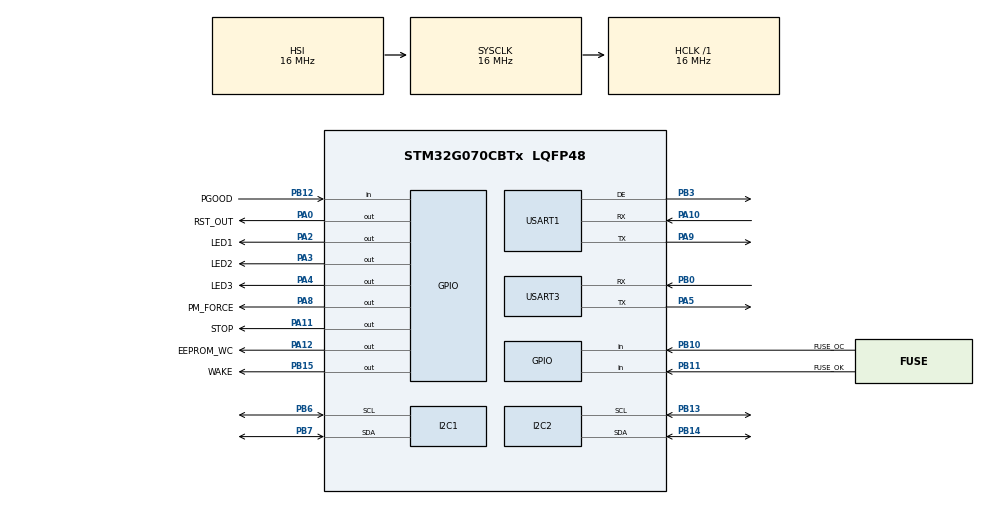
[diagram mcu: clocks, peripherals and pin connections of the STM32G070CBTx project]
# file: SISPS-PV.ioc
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Mcu.Family=STM32G0
Mcu.Name=STM32G070CBTx
Mcu.Package=LQFP48
PA0.GPIO_Label=RST_OUT
PA0.GPIO_ModeDefaultOutputPP=GPIO_MODE_OUTPUT_OD
PA0.GPIO_PuPd=GPIO_NOPULL
PA0.PinState=GPIO_PIN_SET
PA0.Signal=GPIO_Output
PA10.Mode=Asynchronous
PA10.Signal=USART1_RX
PA11\ [PA9].GPIO_Label=STOP
PA11\ [PA9].Signal=GPIO_Output
PA12\ [PA10].GPIO_Label=EEPROM_WC
PA12\ [PA10].PinState=GPIO_PIN_SET
PA12\ [PA10].Signal=GPIO_Output
PA13.Mode=Serial_Wire
PA13.Signal=SYS_SWDIO
PA14-BOOT0.Mode=Serial_Wire
PA14-BOOT0.Signal=SYS_SWCLK
PA2.GPIO_Label=LED1
PA2.Signal=GPIO_Output
PA3.GPIO_Label=LED2
PA3.Signal=GPIO_Output
PA4.GPIO_Label=LED3
PA4.Signal=GPIO_Output
PA5.Mode=Asynchronous
PA5.Signal=USART3_TX
PA8.GPIO_Label=PM_FORCE
PA8.Signal=GPIO_Output
PA9.Mode=Asynchronous
PA9.Signal=USART1_TX
PB0.Mode=Asynchronous
PB0.Signal=USART3_RX
PB10.GPIO_Label=FUSE_OC
PB10.Signal=GPIO_Input
PB11.GPIO_Label=FUSE_OK
PB11.Signal=GPIO_Input
PB12.GPIO_Label=PGOOD
PB12.Signal=GPIO_Input
PB13.Mode=I2C
PB13.Signal=I2C2_SCL
PB14.Mode=I2C
PB14.Signal=I2C2_SDA
PB15.GPIO_Label=WAKE
PB15.Signal=GPIO_Output
PB3.Mode=Hardware Flow Control (RS485)
PB3.Signal=USART1_DE
PB6.Mode=I2C
PB6.Signal=I2C1_SCL
PB7.Mode=I2C
PB7.Signal=I2C1_SDA
ProjectManager.HeapSize=0x200
ProjectManager.StackSize=0x400
ProjectManager.TargetToolchain=STM32CubeIDE
RCC.AHBFreq_Value=16000000
RCC.CortexFreq_Value=16000000
RCC.EXTERNAL_CLOCK_VALUE=48000
RCC.HCLKFreq_Value=16000000
RCC.HSE_VALUE=8000000
RCC.HSI_VALUE=16000000
RCC.LSE_VALUE=32768
RCC.SYSCLKFreq_VALUE=16000000
RCC.VCOOutputFreq_Value=128000000
USART1.VirtualMode-Asynchronous=VM_ASYNC
USART1.VirtualMode-Hardware\ Flow\ Control\ (RS485)=VM_ASYNC
USART3.SwapParam=ADVFEATURE_SWAP_ENABLE
USART3.VirtualMode-Asynchronous=VM_ASYNC
VP_SYS_VS_DBSignals.Mode=DisableDeadBatterySignals
board=custom

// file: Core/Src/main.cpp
/* USER CODE BEGIN Header */
/**
 ******************************************************************************
 * @file           : main.cpp
 * @brief          : Main program file for SISPS-PV.
 * @author			: Lawrence Stanton
 ******************************************************************************
 * @attention
 *
 * © LD Stanton 2022
 *
 * This file and its content are the copyright property of the author. All
 * rights are reserved. No warranty is given. No liability is assumed.
 * Confidential unless licensed otherwise. If licensed, refer to the
 * accompanying file "LICENCE" for license details.
 *
 * Copyright (c) 2022 STMicroelectronics.
 * All rights reserved.
 *
 ******************************************************************************
 */
/* USER CODE END Header */
#include "main.hpp"

/* USER CODE BEGIN Includes */
#include "SISPSPV.hpp"
/* USER CODE END Includes */

/* USER CODE BEGIN PTD */
using namespace std;

/* USER CODE END PTD */

I2C_HandleTypeDef hi2c1;
I2C_HandleTypeDef hi2c2;

UART_HandleTypeDef huart1;
UART_HandleTypeDef huart3;

/* USER CODE BEGIN PV */
I2C_HandleTypeDef *sm72445_hi2c = &hi2c2;
I2C_HandleTypeDef *tmp116_hi2c = &hi2c1;
I2C_HandleTypeDef *hdc1080_hi2c = &hi2c2;
/* USER CODE END PV */

void SystemClock_Config(void);
static void MX_GPIO_Init(void);
static void MX_I2C1_Init(void);
static void MX_I2C2_Init(void);
static void MX_USART1_UART_Init(void);
static void MX_USART3_UART_Init(void);

/* USER CODE BEGIN 0 */
TMP116 tmp = TMP116(TMP116::I2CAddr::ADDR0);
/* USER CODE END 0 */

int main(void) {

	/* MCU Configuration--------------------------------------------------------*/

	/* Reset of all peripherals, Initializes the Flash interface and the Systick. */
	HAL_Init();

	/* Configure the system clock */
	SystemClock_Config();

	/* Initialize all configured peripherals */
	MX_GPIO_Init();
	MX_I2C1_Init();
	MX_I2C2_Init();
	MX_USART1_UART_Init();
	MX_USART3_UART_Init();
	/* USER CODE BEGIN 2 */
	uint16_t devID;
	float T;
	UNUSED(devID);
	UNUSED(T);
	tmp.setConversionMode();

	/* USER CODE END 2 */

	/* Infinite loop */
	while (1) {
		devID = tmp.getDevID();
		T = tmp.getTemperature();
		HAL_Delay(100);
	}
}

void SystemClock_Config(void) {
	RCC_OscInitTypeDef RCC_OscInitStruct = { 0 };
	RCC_ClkInitTypeDef RCC_ClkInitStruct = { 0 };

	/** Configure the main internal regulator output voltage
	 */
	HAL_PWREx_ControlVoltageScaling(PWR_REGULATOR_VOLTAGE_SCALE1);

	/** Initializes the RCC Oscillators according to the specified parameters
	 * in the RCC_OscInitTypeDef structure.
	 */
	RCC_OscInitStruct.OscillatorType = RCC_OSCILLATORTYPE_HSI;
	RCC_OscInitStruct.HSIState = RCC_HSI_ON;
	RCC_OscInitStruct.HSIDiv = RCC_HSI_DIV1;
	RCC_OscInitStruct.HSICalibrationValue = RCC_HSICALIBRATION_DEFAULT;
	RCC_OscInitStruct.PLL.PLLState = RCC_PLL_NONE;
	if (HAL_RCC_OscConfig(&RCC_OscInitStruct) != HAL_OK) {
		Error_Handler();
	}

	/** Initializes the CPU, AHB and APB buses clocks
	 */
	RCC_ClkInitStruct.ClockType = RCC_CLOCKTYPE_HCLK | RCC_CLOCKTYPE_SYSCLK
			| RCC_CLOCKTYPE_PCLK1;
	RCC_ClkInitStruct.SYSCLKSource = RCC_SYSCLKSOURCE_HSI;
	RCC_ClkInitStruct.AHBCLKDivider = RCC_SYSCLK_DIV1;
	RCC_ClkInitStruct.APB1CLKDivider = RCC_HCLK_DIV1;

	if (HAL_RCC_ClockConfig(&RCC_ClkInitStruct, FLASH_LATENCY_0) != HAL_OK) {
		Error_Handler();
	}
}

static void MX_I2C1_Init(void) {

	hi2c1.Instance = I2C1;
	hi2c1.Init.Timing = 0x00303D5B;
	hi2c1.Init.OwnAddress1 = 0;
	hi2c1.Init.AddressingMode = I2C_ADDRESSINGMODE_7BIT;
	hi2c1.Init.DualAddressMode = I2C_DUALADDRESS_DISABLE;
	hi2c1.Init.OwnAddress2 = 0;
	hi2c1.Init.OwnAddress2Masks = I2C_OA2_NOMASK;
	hi2c1.Init.GeneralCallMode = I2C_GENERALCALL_DISABLE;
	hi2c1.Init.NoStretchMode = I2C_NOSTRETCH_DISABLE;
	if (HAL_I2C_Init(&hi2c1) != HAL_OK) {
		Error_Handler();
	}

	/** Configure Analogue filter
	 */
	if (HAL_I2CEx_ConfigAnalogFilter(&hi2c1, I2C_ANALOGFILTER_ENABLE)
			!= HAL_OK) {
		Error_Handler();
	}

	/** Configure Digital filter
	 */
	if (HAL_I2CEx_ConfigDigitalFilter(&hi2c1, 0) != HAL_OK) {
		Error_Handler();
	}

}

static void MX_I2C2_Init(void) {

	hi2c2.Instance = I2C2;
	hi2c2.Init.Timing = 0x00303D5B;
	hi2c2.Init.OwnAddress1 = 0;
	hi2c2.Init.AddressingMode = I2C_ADDRESSINGMODE_7BIT;
	hi2c2.Init.DualAddressMode = I2C_DUALADDRESS_DISABLE;
	hi2c2.Init.OwnAddress2 = 0;
	hi2c2.Init.OwnAddress2Masks = I2C_OA2_NOMASK;
	hi2c2.Init.GeneralCallMode = I2C_GENERALCALL_DISABLE;
	hi2c2.Init.NoStretchMode = I2C_NOSTRETCH_DISABLE;
	if (HAL_I2C_Init(&hi2c2) != HAL_OK) {
		Error_Handler();
	}

	/** Configure Analogue filter
	 */
	if (HAL_I2CEx_ConfigAnalogFilter(&hi2c2, I2C_ANALOGFILTER_ENABLE)
			!= HAL_OK) {
		Error_Handler();
	}

	/** Configure Digital filter
	 */
	if (HAL_I2CEx_ConfigDigitalFilter(&hi2c2, 0) != HAL_OK) {
		Error_Handler();
	}

}

static void MX_USART1_UART_Init(void) {

	huart1.Instance = USART1;
	huart1.Init.BaudRate = 115200;
	huart1.Init.WordLength = UART_WORDLENGTH_8B;
	huart1.Init.StopBits = UART_STOPBITS_1;
	huart1.Init.Parity = UART_PARITY_NONE;
	huart1.Init.Mode = UART_MODE_TX_RX;
	huart1.Init.HwFlowCtl = UART_HWCONTROL_NONE;
	huart1.Init.OverSampling = UART_OVERSAMPLING_16;
	huart1.Init.OneBitSampling = UART_ONE_BIT_SAMPLE_DISABLE;
	huart1.Init.ClockPrescaler = UART_PRESCALER_DIV1;
	huart1.AdvancedInit.AdvFeatureInit = UART_ADVFEATURE_NO_INIT;
	if (HAL_RS485Ex_Init(&huart1, UART_DE_POLARITY_HIGH, 0, 0) != HAL_OK) {
		Error_Handler();
	}
	if (HAL_UARTEx_SetTxFifoThreshold(&huart1, UART_TXFIFO_THRESHOLD_1_8)
			!= HAL_OK) {
		Error_Handler();
	}
	if (HAL_UARTEx_SetRxFifoThreshold(&huart1, UART_RXFIFO_THRESHOLD_1_8)
			!= HAL_OK) {
		Error_Handler();
	}
	if (HAL_UARTEx_DisableFifoMode(&huart1) != HAL_OK) {
		Error_Handler();
	}

}

static void MX_USART3_UART_Init(void) {

	huart3.Instance = USART3;
	huart3.Init.BaudRate = 115200;
	huart3.Init.WordLength = UART_WORDLENGTH_8B;
	huart3.Init.StopBits = UART_STOPBITS_1;
	huart3.Init.Parity = UART_PARITY_NONE;
	huart3.Init.Mode = UART_MODE_TX_RX;
	huart3.Init.HwFlowCtl = UART_HWCONTROL_NONE;
	huart3.Init.OverSampling = UART_OVERSAMPLING_16;
	huart3.Init.OneBitSampling = UART_ONE_BIT_SAMPLE_DISABLE;
	huart3.Init.ClockPrescaler = UART_PRESCALER_DIV1;
	huart3.AdvancedInit.AdvFeatureInit = UART_ADVFEATURE_SWAP_INIT;
	huart3.AdvancedInit.Swap = UART_ADVFEATURE_SWAP_ENABLE;
	if (HAL_UART_Init(&huart3) != HAL_OK) {
		Error_Handler();
	}

}

static void MX_GPIO_Init(void) {
	GPIO_InitTypeDef GPIO_InitStruct = { 0 };

	/* GPIO Ports Clock Enable */
	__HAL_RCC_GPIOA_CLK_ENABLE();
	__HAL_RCC_GPIOB_CLK_ENABLE();

	/*Configure GPIO pin Output Level */
	HAL_GPIO_WritePin(GPIOA, RST_OUT_Pin | EEPROM_WC_Pin, GPIO_PIN_SET);

	/*Configure GPIO pin Output Level */
	HAL_GPIO_WritePin(GPIOA,
	LED1_Pin | LED2_Pin | LED3_Pin | PM_FORCE_Pin | STOP_Pin, GPIO_PIN_RESET);

	/*Configure GPIO pin Output Level */
	HAL_GPIO_WritePin(WAKE_GPIO_Port, WAKE_Pin, GPIO_PIN_RESET);

	/*Configure GPIO pin : RST_OUT_Pin */
	GPIO_InitStruct.Pin = RST_OUT_Pin;
	GPIO_InitStruct.Mode = GPIO_MODE_OUTPUT_OD;
	GPIO_InitStruct.Pull = GPIO_NOPULL;
	GPIO_InitStruct.Speed = GPIO_SPEED_FREQ_LOW;
	HAL_GPIO_Init(RST_OUT_GPIO_Port, &GPIO_InitStruct);

	/*Configure GPIO pins : LED1_Pin LED2_Pin LED3_Pin PM_FORCE_Pin
	 STOP_Pin EEPROM_WC_Pin */
	GPIO_InitStruct.Pin = LED1_Pin | LED2_Pin | LED3_Pin | PM_FORCE_Pin
			| STOP_Pin | EEPROM_WC_Pin;
	GPIO_InitStruct.Mode = GPIO_MODE_OUTPUT_PP;
	GPIO_InitStruct.Pull = GPIO_NOPULL;
	GPIO_InitStruct.Speed = GPIO_SPEED_FREQ_LOW;
	HAL_GPIO_Init(GPIOA, &GPIO_InitStruct);

	/*Configure GPIO pins : FUSE_OC_Pin FUSE_OK_Pin PGOOD_Pin */
	GPIO_InitStruct.Pin = FUSE_OC_Pin | FUSE_OK_Pin | PGOOD_Pin;
	GPIO_InitStruct.Mode = GPIO_MODE_INPUT;
	GPIO_InitStruct.Pull = GPIO_NOPULL;
	HAL_GPIO_Init(GPIOB, &GPIO_InitStruct);

	/*Configure GPIO pin : WAKE_Pin */
	GPIO_InitStruct.Pin = WAKE_Pin;
	GPIO_InitStruct.Mode = GPIO_MODE_OUTPUT_PP;
	GPIO_InitStruct.Pull = GPIO_NOPULL;
	GPIO_InitStruct.Speed = GPIO_SPEED_FREQ_LOW;
	HAL_GPIO_Init(WAKE_GPIO_Port, &GPIO_InitStruct);

}

void Error_Handler(void) {
	__disable_irq();
	while (1) {
	}
}
